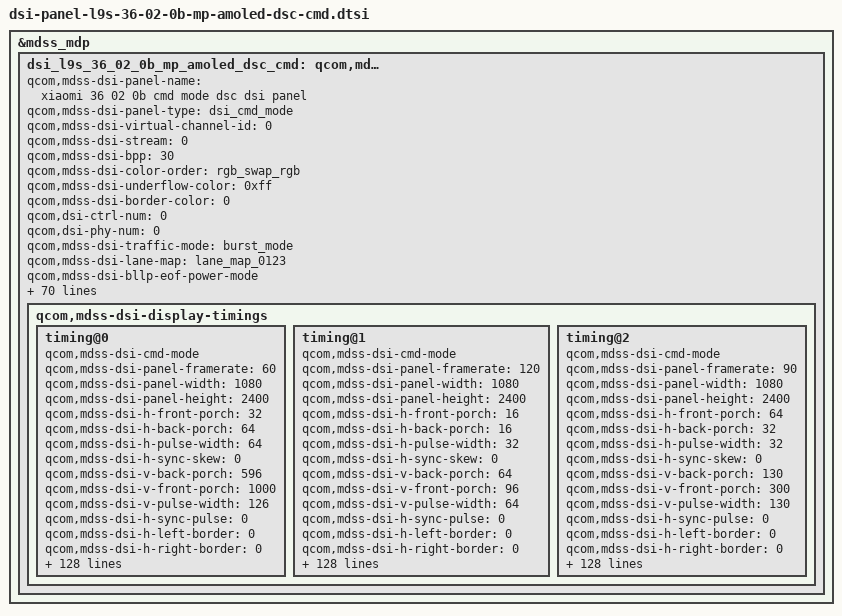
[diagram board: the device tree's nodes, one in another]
&mdss_mdp {
	dsi_l9s_36_02_0b_mp_amoled_dsc_cmd: qcom,mdss_dsi_l9s_36_02_0b_mp_amoled_dsc_cmd {
		qcom,mdss-dsi-panel-name = "xiaomi 36 02 0b cmd mode dsc dsi panel";
		qcom,mdss-dsi-panel-type = "dsi_cmd_mode";
		qcom,mdss-dsi-virtual-channel-id = <0>;
		qcom,mdss-dsi-stream = <0>;
		qcom,mdss-dsi-bpp = <30>;
		qcom,mdss-dsi-color-order = "rgb_swap_rgb";
		qcom,mdss-dsi-underflow-color = <0xff>;
		qcom,mdss-dsi-border-color = <0>;

		qcom,dsi-ctrl-num = <0>;
		qcom,dsi-phy-num = <0>;

		qcom,mdss-dsi-traffic-mode = "burst_mode";
		qcom,mdss-dsi-lane-map = "lane_map_0123";
		qcom,mdss-dsi-bllp-eof-power-mode;
		qcom,mdss-dsi-bllp-power-mode;
		qcom,mdss-dsi-lane-0-state;
		qcom,mdss-dsi-lane-1-state;
		qcom,mdss-dsi-lane-2-state;
		qcom,mdss-dsi-lane-3-state;
		qcom,mdss-dsi-dma-trigger = "trigger_sw";
		qcom,mdss-dsi-mdp-trigger = "none";
		qcom,mdss-dsi-reset-sequence =  <1 11>, <0 1>, <1 11>;
		qcom,mdss-pan-physical-width-dimension = <683>;
		qcom,mdss-pan-physical-height-dimension = <1517>;
		qcom,mdss-dsi-te-pin-select = <1>;
		qcom,mdss-dsi-wr-mem-start = <0x2c>;
		qcom,mdss-dsi-wr-mem-continue = <0x3c>;
		qcom,mdss-dsi-te-dcs-command = <1>;
		qcom,mdss-dsi-te-check-enable;
		qcom,mdss-dsi-te-using-te-pin;
		qcom,mdss-dsi-tx-eot-append;
		qcom,mdss-dsi-lp11-init;

		qcom,mdss-dsi-bl-inverted-dbv;
		qcom,bl-update-flag = "delay_until_first_frame";
		qcom,mdss-dsi-panel-mode-switch;

		qcom,mdss-dsi-panel-hdr-enabled;
		qcom,mdss-dsi-panel-hdr-color-primaries = <14500 15500 32000 17000 15500 30000 8000 3000>;
		qcom,mdss-dsi-panel-peak-brightness = <4200000>;
		qcom,mdss-dsi-panel-blackness-level = <3230>;

		qcom,mdss-dsi-display-timings {
			timing@0{
				qcom,mdss-dsi-cmd-mode;
				qcom,mdss-dsi-panel-framerate = <60>;
				qcom,mdss-dsi-panel-width = <1080>;
				qcom,mdss-dsi-panel-height = <2400>;
				qcom,mdss-dsi-h-front-porch = <32>;
				qcom,mdss-dsi-h-back-porch = <64>;
				qcom,mdss-dsi-h-pulse-width = <64>;
				qcom,mdss-dsi-h-sync-skew = <0>;
				qcom,mdss-dsi-v-back-porch = <596>;
				qcom,mdss-dsi-v-front-porch = <1000>;
				qcom,mdss-dsi-v-pulse-width = <126>;
				qcom,mdss-dsi-h-sync-pulse = <0>;
				qcom,mdss-dsi-h-left-border = <0>;
				qcom,mdss-dsi-h-right-border = <0>;
				qcom,mdss-dsi-v-top-border = <0>;
				qcom,mdss-dsi-v-bottom-border = <0>;
				qcom,mdss-dsi-panel-clockrate = <831000000>;
				qcom,mdss-dsi-panel-jitter = <0x5 0x1>;
				qcom,mdss-mdp-transfer-time-us = <14000>;
				qcom,mdss-dsi-on-command = [
					/* Page 0 */
					39 00 00 00 00 00 06 F0 55 AA 52 08 00
					39 00 00 40 00 00 02 6F 1C
					/* Gain mapping */
					39 00 00 40 00 00 06 C0 10 20 30 40 50
					/* VBP & VFP */
					39 00 00 40 00 00 05 3B 00 10 00 04
					/* DSC Setting */
					39 00 00 40 00 00 02 90 01
					39 00 00 40 00 00 13 91 89 28 00 0C C2 00 03 1C 01 7E 00 0F 08 BB 04 3D 10 F0
					39 00 00 40 00 00 02 03 01
					/* Dimming OFF Setting */
					39 00 00 40 00 00 02 53 20
					/* TE ON Setting */
					39 00 00 40 00 00 02 35 00
					/* CASET/RASET Setting */
					39 00 00 40 00 00 05 2A 00 00 04 37 /* CASET 1080 */
					39 00 00 40 00 00 05 2B 00 00 09 5F /* PASET 2400 */
					/* Frame Rate 60Hz */
					39 00 00 40 00 00 02 2F 03
					/* GIR OFF */
					39 00 00 40 00 00 02 5F 01
					/* ESD Error flag  Active low */
					39 00 00 40 00 00 06 F0 55 AA 52 08 00
					39 00 00 40 00 00 03 BE 0E 0B
					39 00 00 40 00 00 02 6F 05
					39 00 00 00 00 00 02 BE 8A
					/* Round Off */
					39 00 00 40 00 00 06 F0 55 AA 52 08 07
					39 00 00 40 00 00 02 C0 01
					39 00 00 40 00 00 02 C1 00
					39 00 00 40 00 00 02 C2 00
					39 00 00 40 00 00 02 C3 00
					39 00 00 40 00 00 02 C4 00
					39 00 00 40 00 00 02 C5 00
					39 00 00 40 00 00 02 C6 00
					39 00 00 40 00 00 02 C7 00
					39 00 00 40 00 00 02 C8 00
					39 00 00 40 00 00 02 C9 00
					39 00 00 40 00 00 02 CA 00
					39 00 00 40 00 00 02 CB 00
					39 00 00 00 00 00 02 CC 00
					/*OSC Setting*/
					39 00 00 40 00 00 05 FF AA 55 A5 81
					39 00 00 40 00 00 02 6F 0F
					39 00 00 40 00 00 03 FD 01 92
					39 00 00 00 00 00 02 2C 00
					39 00 00 00 00 00 06 F0 55 AA 52 08 07
					39 00 00 40 00 00 07 C0 01 01 00 00 00 55
					39 00 00 40 00 00 2C CD 21 00 22 84 22 84 00 00 3F E6 A7 10 3F E6 A7 10 80 04 A7 54 10 81 BD 15 82 1B 73 33 B0 22 84 0F A2 A2 00 00 00 00 00 00 00 00 00
					39 00 00 40 00 00 2C CE 27 00 22 84 22 84 00 00 00 00 00 00 3F E6 A7 10 80 00 00 00 00 82 1C 15 82 7A 73 33 B0 00 00 03 5E A2 00 00 00 00 00 00 00 00 00
					39 00 00 40 00 00 2C CF 2D 00 22 84 22 84 00 00 3F E6 A7 10 80 00 00 00 00 00 00 00 00 81 BD 74 82 1B D2 33 20 00 00 0C A2 5E 00 00 00 00 00 00 00 00 00
					39 00 00 00 00 00 2C D0 2B 00 22 84 22 84 00 00 00 00 00 00 80 00 00 00 7F FB 58 AB F0 82 1C 74 82 7A D2 33 2F DD 7C 00 5E 5E 00 00 00 00 00 00 00 00 00
					//FPR_W_THD
					39 00 00 40 00 00 02 D9 01
					39 00 00 40 00 00 06 F0 55 AA 52 08 00
					//DBV_DIM_FP
					39 00 00 40 00 00 02 6F 17
					39 00 00 40 00 00 03 B2 01 48
					//EM_DT_FP
					39 00 00 40 00 00 02 6F 1F
					39 00 00 00 00 00 03 B2 00 0C
					//sRGB_EN = 1
					39 00 00 40 00 00 02 DE 01
					//sRGB_Ratio_R/G/B (0 ~ 256 --> 0 ~ 1.0)
					39 00 00 40 00 00 02 6F 01
					39 00 00 40 00 00 07 DE 01 00 01 00 01 00
					39 00 00 40 00 00 06 F0 55 AA 52 08 02
					//Data + Gamma Mode
					39 00 00 40 00 00 02 D1 41
					//FPR_GAMMA_REDUCE_X/Y
					39 00 00 40 00 00 02 6F 02
					39 00 00 40 00 00 02 D1 00
					//FPR1_CENTER_X/Y_REF
					39 00 00 40 00 00 02 6F 03
					39 00 00 40 00 00 05 D1 02 1C 08 74
					//FPR1_START_X/Y_REF
					39 00 00 40 00 00 02 6F 07
					39 00 00 40 00 00 05 D1 01 BD 08 15
					//FPR1_END_X/Y_REF
					39 00 00 40 00 00 02 6F 0B
					39 00 00 00 00 00 05 D1 02 7A 08 D2
					//FPR_LHBM_R/G/B
					39 00 00 40 00 00 02 6F 0F
					39 00 00 40 00 00 07 D1 3F FC 3F FC 3F FC
					//GAMMA_TOUCH_R/G/B
					39 00 00 40 00 00 02 6F 08
					39 00 00 40 00 00 07 D0 0C 7B 0B 70 0C B0
					//FPR1_EN = 1
					39 00 00 40 00 00 02 88 01
					//FPR_CENTER_XY
					39 00 00 40 00 00 02 6F 01
					39 00 00 00 00 00 05 88 02 1C 08 73
					39 00 00 40 00 00 06 F0 55 AA 52 08 00
					39 00 00 40 00 00 02 B2 19
					39 00 00 40 00 00 02 6F 02
					39 00 00 00 00 00 03 B2 08 08
					39 00 00 40 00 00 02 6F 05
					39 00 00 00 00 00 02 BE 88
					/* Sleep Out */
					39 00 00 00 78 00 02 11 00
					/* Display On */
					39 00 00 00 00 00 02 29 00];
				qcom,mdss-dsi-off-command = [
					39 00 00 00 0A 00 02 28 00
					39 00 00 00 78 00 02 10 00];
				qcom,mdss-dsi-on-command-state = "dsi_lp_mode";
				qcom,mdss-dsi-off-command-state = "dsi_lp_mode";

				qcom,mdss-dsi-timing-switch-command = [
					/* Frame Rate 60Hz*/
					39 00 00 00 00 00 02 2F 03
				];
				qcom,mdss-dsi-timing-switch-command-update = <0x2F 0 1>;
				qcom,mdss-dsi-timing-switch-command-state = "dsi_hs_mode";

				qcom,mdss-dsi-nolp-command = [
					39 00 00 00 00 00 06 F0 55 AA 52 08 00
					39 00 00 40 00 00 02 38 00
					39 00 00 00 00 00 02 2C 00];
				qcom,mdss-dsi-nolp-command-state = "dsi_hs_mode";

				qcom,compression-mode = "dsc";
				qcom,mdss-dsc-version = <0x11>;
				qcom,mdss-dsc-scr-version = <0x0>;
				qcom,mdss-dsc-slice-height = <12>;
				qcom,mdss-dsc-slice-width = <1080>;
				qcom,mdss-dsc-slice-per-pkt = <1>;
				qcom,mdss-dsc-bit-per-component = <10>;
				qcom,mdss-dsc-bit-per-pixel = <8>;
				qcom,mdss-dsc-block-prediction-enable;
			};
			timing@1{
				qcom,mdss-dsi-cmd-mode;
				qcom,mdss-dsi-panel-framerate = <120>;
				qcom,mdss-dsi-panel-width = <1080>;
				qcom,mdss-dsi-panel-height = <2400>;
				qcom,mdss-dsi-h-front-porch = <16>;
				qcom,mdss-dsi-h-back-porch = <16>;
				qcom,mdss-dsi-h-pulse-width = <32>;
				qcom,mdss-dsi-h-sync-skew = <0>;
				qcom,mdss-dsi-v-back-porch = <64>;
				qcom,mdss-dsi-v-front-porch = <96>;
				qcom,mdss-dsi-v-pulse-width = <64>;
				qcom,mdss-dsi-h-sync-pulse = <0>;
				qcom,mdss-dsi-h-left-border = <0>;
				qcom,mdss-dsi-h-right-border = <0>;
				qcom,mdss-dsi-v-top-border = <0>;
				qcom,mdss-dsi-v-bottom-border = <0>;
				qcom,mdss-dsi-panel-clockrate = <831000000>;
				qcom,mdss-dsi-panel-jitter = <0x5 0x1>;
				qcom,mdss-mdp-transfer-time-us = <8000>;
				qcom,mdss-dsi-on-command = [
					/* Page 0 */
					39 00 00 00 00 00 06 F0 55 AA 52 08 00
					39 00 00 40 00 00 02 6F 1C
					/* Gain mapping */
					39 00 00 40 00 00 06 C0 10 20 30 40 50
					/* VBP & VFP */
					39 00 00 40 00 00 05 3B 00 10 00 04
					/* DSC Setting */
					39 00 00 40 00 00 02 90 01
					39 00 00 40 00 00 13 91 89 28 00 0C C2 00 03 1C 01 7E 00 0F 08 BB 04 3D 10 F0
					39 00 00 40 00 00 02 03 01
					/* Dimming OFF Setting */
					39 00 00 40 00 00 02 53 20
					/* TE ON Setting */
					39 00 00 40 00 00 02 35 00
					/* CASET/RASET Setting */
					39 00 00 40 00 00 05 2A 00 00 04 37 /* CASET 1080 */
					39 00 00 40 00 00 05 2B 00 00 09 5F /* PASET 2400 */
					/* Frame Rate 120Hz */
					39 00 00 40 00 00 02 2F 01
					/* GIR OFF */
					39 00 00 40 00 00 02 5F 01
					/* ESD Error flag  Active low */
					39 00 00 40 00 00 06 F0 55 AA 52 08 00
					39 00 00 40 00 00 03 BE 0E 0B
					39 00 00 40 00 00 02 6F 05
					39 00 00 00 00 00 02 BE 8A
					/* Round Off */
					39 00 00 40 00 00 06 F0 55 AA 52 08 07
					39 00 00 40 00 00 02 C0 01
					39 00 00 40 00 00 02 C1 00
					39 00 00 40 00 00 02 C2 00
					39 00 00 40 00 00 02 C3 00
					39 00 00 40 00 00 02 C4 00
					39 00 00 40 00 00 02 C5 00
					39 00 00 40 00 00 02 C6 00
					39 00 00 40 00 00 02 C7 00
					39 00 00 40 00 00 02 C8 00
					39 00 00 40 00 00 02 C9 00
					39 00 00 40 00 00 02 CA 00
					39 00 00 40 00 00 02 CB 00
					39 00 00 00 00 00 02 CC 00
					/*OSC Setting*/
					39 00 00 40 00 00 05 FF AA 55 A5 81
					39 00 00 40 00 00 02 6F 0F
					39 00 00 40 00 00 03 FD 01 92
					39 00 00 00 00 00 02 2C 00
					39 00 00 00 00 00 06 F0 55 AA 52 08 07
					39 00 00 40 00 00 07 C0 01 01 00 00 00 55
					39 00 00 40 00 00 2C CD 21 00 22 84 22 84 00 00 3F E6 A7 10 3F E6 A7 10 80 04 A7 54 10 81 BD 15 82 1B 73 33 B0 22 84 0F A2 A2 00 00 00 00 00 00 00 00 00
					39 00 00 40 00 00 2C CE 27 00 22 84 22 84 00 00 00 00 00 00 3F E6 A7 10 80 00 00 00 00 82 1C 15 82 7A 73 33 B0 00 00 03 5E A2 00 00 00 00 00 00 00 00 00
					39 00 00 40 00 00 2C CF 2D 00 22 84 22 84 00 00 3F E6 A7 10 80 00 00 00 00 00 00 00 00 81 BD 74 82 1B D2 33 20 00 00 0C A2 5E 00 00 00 00 00 00 00 00 00
					39 00 00 00 00 00 2C D0 2B 00 22 84 22 84 00 00 00 00 00 00 80 00 00 00 7F FB 58 AB F0 82 1C 74 82 7A D2 33 2F DD 7C 00 5E 5E 00 00 00 00 00 00 00 00 00
					//FPR_W_THD
					39 00 00 40 00 00 02 D9 01
					39 00 00 40 00 00 06 F0 55 AA 52 08 00
					//DBV_DIM_FP
					39 00 00 40 00 00 02 6F 17
					39 00 00 40 00 00 03 B2 01 48
					//EM_DT_FP
					39 00 00 40 00 00 02 6F 1F
					39 00 00 00 00 00 03 B2 00 0C
					//sRGB_EN = 1
					39 00 00 40 00 00 02 DE 01
					//sRGB_Ratio_R/G/B (0 ~ 256 --> 0 ~ 1.0)
					39 00 00 40 00 00 02 6F 01
					39 00 00 40 00 00 07 DE 01 00 01 00 01 00
					39 00 00 40 00 00 06 F0 55 AA 52 08 02
					//Data + Gamma Mode
					39 00 00 40 00 00 02 D1 41
					//FPR_GAMMA_REDUCE_X/Y
					39 00 00 40 00 00 02 6F 02
					39 00 00 40 00 00 02 D1 00
					//FPR1_CENTER_X/Y_REF
					39 00 00 40 00 00 02 6F 03
					39 00 00 40 00 00 05 D1 02 1C 08 74
					//FPR1_START_X/Y_REF
					39 00 00 40 00 00 02 6F 07
					39 00 00 40 00 00 05 D1 01 BD 08 15
					//FPR1_END_X/Y_REF
					39 00 00 40 00 00 02 6F 0B
					39 00 00 00 00 00 05 D1 02 7A 08 D2
					//FPR_LHBM_R/G/B
					39 00 00 40 00 00 02 6F 0F
					39 00 00 40 00 00 07 D1 3F FC 3F FC 3F FC
					//GAMMA_TOUCH_R/G/B
					39 00 00 40 00 00 02 6F 08
					39 00 00 40 00 00 07 D0 0C 7B 0B 70 0C B0
					//FPR1_EN = 1
					39 00 00 40 00 00 02 88 01
					//FPR_CENTER_XY
					39 00 00 40 00 00 02 6F 01
					39 00 00 00 00 00 05 88 02 1C 08 73
					39 00 00 40 00 00 06 F0 55 AA 52 08 00
					39 00 00 40 00 00 02 B2 19
					39 00 00 40 00 00 02 6F 02
					39 00 00 00 00 00 03 B2 08 08
					39 00 00 40 00 00 02 6F 05
					39 00 00 00 00 00 02 BE 88
					/* Sleep Out */
					39 00 00 00 78 00 02 11 00
					/* Display On */
					39 00 00 00 00 00 02 29 00];
				qcom,mdss-dsi-off-command = [
					39 00 00 00 14 00 02 28 00
					39 00 00 00 78 00 02 10 00];
				qcom,mdss-dsi-on-command-state = "dsi_lp_mode";
				qcom,mdss-dsi-off-command-state = "dsi_lp_mode";

				qcom,mdss-dsi-timing-switch-command = [
					/* Frame Rate 120Hz */
					39 00 00 00 00 00 02 2F 01
				];
				qcom,mdss-dsi-timing-switch-command-update = <0x2F 0 1>;
				qcom,mdss-dsi-timing-switch-command-state = "dsi_hs_mode";

				qcom,mdss-dsi-nolp-command = [
					39 00 00 00 00 00 06 F0 55 AA 52 08 00
					39 00 00 40 00 00 02 38 00
					39 00 00 00 00 00 02 2C 00];
				qcom,mdss-dsi-nolp-command-state = "dsi_hs_mode";

				qcom,compression-mode = "dsc";
				qcom,mdss-dsc-version = <0x11>;
				qcom,mdss-dsc-scr-version = <0x0>;
				qcom,mdss-dsc-slice-height = <12>;
				qcom,mdss-dsc-slice-width = <1080>;
				qcom,mdss-dsc-slice-per-pkt = <1>;
				qcom,mdss-dsc-bit-per-component = <10>;
				qcom,mdss-dsc-bit-per-pixel = <8>;
				qcom,mdss-dsc-block-prediction-enable;
			};
			timing@2{
				qcom,mdss-dsi-cmd-mode;
				qcom,mdss-dsi-panel-framerate = <90>;
				qcom,mdss-dsi-panel-width = <1080>;
				qcom,mdss-dsi-panel-height = <2400>;
				qcom,mdss-dsi-h-front-porch = <64>;
				qcom,mdss-dsi-h-back-porch = <32>;
				qcom,mdss-dsi-h-pulse-width = <32>;
				qcom,mdss-dsi-h-sync-skew = <0>;
				qcom,mdss-dsi-v-back-porch = <130>;
				qcom,mdss-dsi-v-front-porch = <300>;
				qcom,mdss-dsi-v-pulse-width = <130>;
				qcom,mdss-dsi-h-sync-pulse = <0>;
				qcom,mdss-dsi-h-left-border = <0>;
				qcom,mdss-dsi-h-right-border = <0>;
				qcom,mdss-dsi-v-top-border = <0>;
				qcom,mdss-dsi-v-bottom-border = <0>;
				qcom,mdss-dsi-panel-clockrate = <831000000>;
				qcom,mdss-dsi-panel-jitter = <0x5 0x1>;
				qcom,mdss-mdp-transfer-time-us = <10000>;
				qcom,mdss-dsi-on-command = [
					/* Page 0 */
					39 00 00 00 00 00 06 F0 55 AA 52 08 00
					39 00 00 40 00 00 02 6F 1C
					/* Gain mapping */
					39 00 00 40 00 00 06 C0 10 20 30 40 50
					/* VBP & VFP */
					39 00 00 40 00 00 05 3B 00 10 00 04
					/* DSC Setting */
					39 00 00 40 00 00 02 90 01
					39 00 00 40 00 00 13 91 89 28 00 0C C2 00 03 1C 01 7E 00 0F 08 BB 04 3D 10 F0
					39 00 00 40 00 00 02 03 01
					/* Dimming OFF Setting */
					39 00 00 40 00 00 02 53 20
					/* TE ON Setting */
					39 00 00 40 00 00 02 35 00
					/* CASET/RASET Setting */
					39 00 00 40 00 00 05 2A 00 00 04 37 /* CASET 1080 */
					39 00 00 40 00 00 05 2B 00 00 09 5F /* PASET 2400 */
					/* Frame Rate 60Hz */
					39 00 00 40 00 00 02 2F 07
					/* GIR OFF */
					39 00 00 40 00 00 02 5F 01
					/* ESD Error flag  Active low */
					39 00 00 40 00 00 06 F0 55 AA 52 08 00
					39 00 00 40 00 00 03 BE 0E 0B
					39 00 00 40 00 00 02 6F 05
					39 00 00 00 00 00 02 BE 8A
					/* Round Off */
					39 00 00 40 00 00 06 F0 55 AA 52 08 07
					39 00 00 40 00 00 02 C0 01
					39 00 00 40 00 00 02 C1 00
					39 00 00 40 00 00 02 C2 00
					39 00 00 40 00 00 02 C3 00
					39 00 00 40 00 00 02 C4 00
					39 00 00 40 00 00 02 C5 00
					39 00 00 40 00 00 02 C6 00
					39 00 00 40 00 00 02 C7 00
					39 00 00 40 00 00 02 C8 00
					39 00 00 40 00 00 02 C9 00
					39 00 00 40 00 00 02 CA 00
					39 00 00 40 00 00 02 CB 00
					39 00 00 00 00 00 02 CC 00
					/*OSC Setting*/
					39 00 00 40 00 00 05 FF AA 55 A5 81
					39 00 00 40 00 00 02 6F 0F
					39 00 00 40 00 00 03 FD 01 92
					39 00 00 00 00 00 02 2C 00
					39 00 00 00 00 00 06 F0 55 AA 52 08 07
					39 00 00 40 00 00 07 C0 01 01 00 00 00 55
					39 00 00 40 00 00 2C CD 21 00 22 84 22 84 00 00 3F E6 A7 10 3F E6 A7 10 80 04 A7 54 10 81 BD 15 82 1B 73 33 B0 22 84 0F A2 A2 00 00 00 00 00 00 00 00 00
					39 00 00 40 00 00 2C CE 27 00 22 84 22 84 00 00 00 00 00 00 3F E6 A7 10 80 00 00 00 00 82 1C 15 82 7A 73 33 B0 00 00 03 5E A2 00 00 00 00 00 00 00 00 00
					39 00 00 40 00 00 2C CF 2D 00 22 84 22 84 00 00 3F E6 A7 10 80 00 00 00 00 00 00 00 00 81 BD 74 82 1B D2 33 20 00 00 0C A2 5E 00 00 00 00 00 00 00 00 00
					39 00 00 00 00 00 2C D0 2B 00 22 84 22 84 00 00 00 00 00 00 80 00 00 00 7F FB 58 AB F0 82 1C 74 82 7A D2 33 2F DD 7C 00 5E 5E 00 00 00 00 00 00 00 00 00
					//FPR_W_THD
					39 00 00 40 00 00 02 D9 01
					39 00 00 40 00 00 06 F0 55 AA 52 08 00
					//DBV_DIM_FP
					39 00 00 40 00 00 02 6F 17
					39 00 00 40 00 00 03 B2 01 48
					//EM_DT_FP
					39 00 00 40 00 00 02 6F 1F
					39 00 00 00 00 00 03 B2 00 0C
					//sRGB_EN = 1
					39 00 00 40 00 00 02 DE 01
					//sRGB_Ratio_R/G/B (0 ~ 256 --> 0 ~ 1.0)
					39 00 00 40 00 00 02 6F 01
					39 00 00 40 00 00 07 DE 01 00 01 00 01 00
					39 00 00 40 00 00 06 F0 55 AA 52 08 02
					//Data + Gamma Mode
					39 00 00 40 00 00 02 D1 41
					//FPR_GAMMA_REDUCE_X/Y
					39 00 00 40 00 00 02 6F 02
					39 00 00 40 00 00 02 D1 00
					//FPR1_CENTER_X/Y_REF
					39 00 00 40 00 00 02 6F 03
					39 00 00 40 00 00 05 D1 02 1C 08 74
					//FPR1_START_X/Y_REF
					39 00 00 40 00 00 02 6F 07
					39 00 00 40 00 00 05 D1 01 BD 08 15
					//FPR1_END_X/Y_REF
					39 00 00 40 00 00 02 6F 0B
					39 00 00 00 00 00 05 D1 02 7A 08 D2
					//FPR_LHBM_R/G/B
					39 00 00 40 00 00 02 6F 0F
					39 00 00 40 00 00 07 D1 3F FC 3F FC 3F FC
					//GAMMA_TOUCH_R/G/B
					39 00 00 40 00 00 02 6F 08
					39 00 00 40 00 00 07 D0 0C 7B 0B 70 0C B0
					//FPR1_EN = 1
					39 00 00 40 00 00 02 88 01
					//FPR_CENTER_XY
					39 00 00 40 00 00 02 6F 01
					39 00 00 00 00 00 05 88 02 1C 08 73
					39 00 00 40 00 00 06 F0 55 AA 52 08 00
					39 00 00 40 00 00 02 B2 19
					39 00 00 40 00 00 02 6F 02
					39 00 00 00 00 00 03 B2 08 08
					39 00 00 40 00 00 02 6F 05
					39 00 00 00 00 00 02 BE 88
					/* Sleep Out */
					39 00 00 00 78 00 02 11 00
					/* Display On */
					39 00 00 00 00 00 02 29 00];
				qcom,mdss-dsi-off-command = [
					39 00 00 00 0A 00 02 28 00
					39 00 00 00 78 00 02 10 00];
				qcom,mdss-dsi-on-command-state = "dsi_lp_mode";
				qcom,mdss-dsi-off-command-state = "dsi_lp_mode";

				qcom,mdss-dsi-timing-switch-command = [
					/* Frame Rate 90Hz */
					39 00 00 00 00 00 02 2F 07
				];
				qcom,mdss-dsi-timing-switch-command-update = <0x2F 0 1>;
				qcom,mdss-dsi-timing-switch-command-state = "dsi_hs_mode";

				qcom,mdss-dsi-nolp-command = [
					39 00 00 00 00 00 06 F0 55 AA 52 08 00
					39 00 00 40 00 00 02 38 00
					39 00 00 00 00 00 02 2C 00];
				qcom,mdss-dsi-nolp-command-state = "dsi_hs_mode";

				qcom,compression-mode = "dsc";
				qcom,mdss-dsc-version = <0x11>;
				qcom,mdss-dsc-scr-version = <0x0>;
				qcom,mdss-dsc-slice-height = <12>;
				qcom,mdss-dsc-slice-width = <1080>;
				qcom,mdss-dsc-slice-per-pkt = <1>;
				qcom,mdss-dsc-bit-per-component = <10>;
				qcom,mdss-dsc-bit-per-pixel = <8>;
				qcom,mdss-dsc-block-prediction-enable;
			};
		};
	};
};

&dsi_l9s_36_02_0b_mp_amoled_dsc_cmd {
	mi,panel-id = <0x004C3953 0x00360200>;
	mi,hbm-51-ctl-flag;
	mi,bl-51ctl-32bit-flag;
	mi,aod-bl-51ctl-flag;
	mi,aod-brightness = <0x1FF 0x03FF>;
	mi,hbm-off-51-index = <0>;
	mi,hbm-fod-off-51-index = <0>;
	mi,hbm-bl-min-level = <1>;
	mi,hbm-bl-max-level = <2047>;
	mi,max-brightness-clone = <4095>;
	mi,thermal-dimming-flag;
	mi,mdss-dsi-panel-dc-type = <0>;
	mi,local-hbm-enabled;
	mi,doze-hbm-dbv-level = <245>;
	mi,doze-lbm-dbv-level = <20>;
	mi,fod-low-brightness-clone-threshold = <38>;
	mi,fod-low-brightness-lux-threshold = <1>;
	mi,mdss-dsi-fac-bl-max-level = <2047>;
	mi,mdss-fac-brightness-max-level = <2047>;
	mi,local-hbm-white-1000nit-update-flag;
	mi,local-hbm-white-110nit-update-flag;
	mi,local-hbm-green-500nit-update-flag;
	mi,local-hbm-alpha-ctrl-aa-area;
	mi,local-hbm-ctrl-b2-reg;
	mi,need-fod-animal-in-normal-enabled;

	mi,flat-need-sync-te;

	mi,panel-hbm-backlight-threshold = <2047>;

	/* IRQF_ONESHOT | IRQF_TRIGGER_LOW */
	mi,esd-err-irq-gpio = <&tlmm 11 0x2008>;

	mi,panel-aod-to-off-command-need-enabled;

	mi,panel-on-dimming-delay = <120>;

	qcom,esd-check-enabled;
	qcom,esd-aod-check-enabled;
	qcom,mdss-dsi-panel-status-check-mode = "reg_read";
	qcom,mdss-dsi-panel-status-offset-command = [
		39 00 00 00 00 00 05 FF AA 55 A5 81
		39 00 00 00 00 00 02 6F 0F];
	qcom,mdss-dsi-panel-status-command = [06 00 00 00 00 00 01 FA];
	qcom,mdss-dsi-panel-status-command-state = "dsi_lp_mode";
	qcom,mdss-dsi-panel-status-offset-command-state = "dsi_lp_mode";
	qcom,mdss-dsi-panel-status-value = <0x00>;
	qcom,mdss-dsi-panel-status-read-length = <1>;

	qcom,mdss-dsi-display-timings {
		timing@0{ /* 60hz */
			/*<flat on gamma, flat off gamma>*/
			mi,mdss-flat-status-control-gamma-cfg = <0x04 0x03>;
			mi,mdss-dsc-panel-id = <0x004C3953 0x00360200>;
			mi,mdss-dsi-dimmingon-command = [39 00 00 00 00 00 02 53 28];
			mi,mdss-dsi-dimmingon-command-state = "dsi_hs_mode";
			mi,mdss-dsi-dimmingoff-command = [39 00 00 00 00 00 02 53 20];
			mi,mdss-dsi-dimmingoff-command-state = "dsi_hs_mode";

			mi,mdss-dsi-hbm-on-command = [39 00 00 00 00 00 03 51 0F FF];
			mi,mdss-dsi-hbm-on-command-state = "dsi_hs_mode";
			mi,mdss-dsi-hbm-off-command = [39 00 00 00 00 00 03 51 07 FF];
			mi,mdss-dsi-hbm-off-command-state = "dsi_hs_mode";

			mi,mdss-dsi-doze-hbm-command = [
				39 00 00 00 00 00 06 F0 55 AA 52 08 00
				39 00 00 40 00 00 05 51 00 F5 03 FF
				39 00 00 40 00 00 02 39 00
				39 00 00 00 00 00 02 2C 00
			];
			mi,mdss-dsi-doze-hbm-command-state = "dsi_lp_mode";
			mi,mdss-dsi-doze-lbm-command = [
				39 00 00 00 00 00 06 F0 55 AA 52 08 00
				39 00 00 40 00 00 05 51 00 14 01 FF
				39 00 00 40 00 00 02 39 00
				39 00 00 00 00 00 02 2C 00
			];
			mi,mdss-dsi-doze-lbm-command-state = "dsi_lp_mode";

			mi,mdss-dsi-doze-hbm-nolp-command = [
				/* AOD off */
				39 00 00 00 00 00 06 F0 55 AA 52 08 00
				39 00 00 40 00 00 05 51 00 F5 03 FF
				39 00 00 40 00 00 02 38 00
				39 00 00 00 00 00 02 2C 00
			];
			mi,mdss-dsi-doze-hbm-nolp-command-state = "dsi_lp_mode";
			mi,mdss-dsi-doze-lbm-nolp-command = [
				/* AOD off */
				39 00 00 00 00 00 06 F0 55 AA 52 08 00
				39 00 00 40 00 00 05 51 00 14 01 FF
				39 00 00 40 00 00 02 38 00
				39 00 00 00 00 00 02 2C 00
			];
			mi,mdss-dsi-doze-lbm-nolp-command-state = "dsi_lp_mode";

			mi,mdss-dsi-doze-none-nolp-command = [
				/* AOD off */
				39 00 00 00 00 00 02 38 00
				39 00 00 00 00 00 02 2C 00
			];
			mi,mdss-dsi-doze-none-nolp-command-state = "dsi_lp_mode";

			mi,mdss-dsi-local-hbm-normal-white-1000nit-command = [
				39 00 00 00 00 00 06 F0 55 AA 52 08 00
				39 00 00 40 00 00 02 6F 17
				39 00 00 40 00 00 03 B2 01 48
				39 00 00 40 00 00 06 F0 55 AA 52 08 02
				39 00 00 40 00 00 02 6F 08
				39 00 00 40 00 00 07 D0 0B 0A 0A EC 0B FD
				39 00 00 40 00 00 02 88 01
				39 00 00 40 00 00 02 6F 01
				39 00 00 40 00 00 05 88 02 1C 08 73
				39 00 00 40 00 00 03 87 1F FF
				39 00 00 00 42 00 02 85 01
			];
			mi,mdss-dsi-local-hbm-normal-white-1000nit-command-update = <0x87 9 2>, <0xD0 5 6>, <0xB2 2 2>;
			mi,mdss-dsi-local-hbm-normal-white-1000nit-command-state = "dsi_hs_mode";

			mi,mdss-dsi-local-hbm-hlpm-white-1000nit-command = [
				/* AOD off */
				39 00 00 00 00 00 06 F0 55 AA 52 08 00
				39 00 00 40 00 00 02 38 00
				39 00 00 00 00 00 02 2C 00
				/* Local HBM setting*/
				39 00 00 00 00 00 06 F0 55 AA 52 08 00
				39 00 00 40 00 00 02 6F 17
				39 00 00 40 00 00 03 B2 01 48
				39 00 00 40 00 00 06 F0 55 AA 52 08 02
				39 00 00 40 00 00 02 6F 08
				39 00 00 40 00 00 07 D0 0B 0A 0A EC 0B FD
				39 00 00 40 00 00 02 88 01
				39 00 00 40 00 00 02 6F 01
				39 00 00 40 00 00 05 88 02 1C 08 73
				39 00 00 40 00 00 03 87 1F FF
				39 00 00 00 42 00 02 85 01
			];
			mi,mdss-dsi-local-hbm-hlpm-white-1000nit-command-update = <0x87 12 2>, <0xD0 8 6>, <0xB2 5 2>;
			mi,mdss-dsi-local-hbm-hlpm-white-1000nit-command-state = "dsi_hs_mode";

			mi,mdss-dsi-local-hbm-normal-white-110nit-command = [
				39 00 00 00 00 00 06 F0 55 AA 52 08 00
				39 00 00 40 00 00 02 6F 17
				39 00 00 40 00 00 03 B2 01 48
				39 00 00 40 00 00 06 F0 55 AA 52 08 02
				39 00 00 40 00 00 02 6F 08
				39 00 00 40 00 00 07 D0 0B 0A 0A EC 0B FD
				39 00 00 40 00 00 02 88 01
				39 00 00 40 00 00 02 6F 01
				39 00 00 40 00 00 05 88 02 1C 08 73
				39 00 00 40 00 00 03 87 1F FF
				39 00 00 00 42 00 02 85 01
			];
			mi,mdss-dsi-local-hbm-normal-white-110nit-command-update = <0x87 9 2>, <0xD0 5 6>, <0xB2 2 2>;
			mi,mdss-dsi-local-hbm-normal-white-110nit-command-state = "dsi_hs_mode";

			mi,mdss-dsi-local-hbm-hlpm-white-110nit-command = [
				39 00 00 00 00 00 06 F0 55 AA 52 08 00
				/* AOD off */
				39 00 00 40 00 00 02 38 00
				39 00 00 00 00 00 02 2C 00
				/* Local HBM setting*/
				39 00 00 00 00 00 06 F0 55 AA 52 08 00
				39 00 00 40 00 00 02 6F 17
				39 00 00 40 00 00 03 B2 01 48
				39 00 00 40 00 00 06 F0 55 AA 52 08 02
				39 00 00 40 00 00 02 6F 08
				39 00 00 40 00 00 07 D0 0B 0A 0A EC 0B FD
				39 00 00 40 00 00 02 88 01
				39 00 00 40 00 00 02 6F 01
				39 00 00 40 00 00 05 88 02 1C 08 73
				39 00 00 40 00 00 03 87 1F FF
				39 00 00 00 42 00 02 85 01
			];
			mi,mdss-dsi-local-hbm-hlpm-white-110nit-command-update = <0x87 12 2>, <0xD0 8 6>, <0xB2 5 2>;
			mi,mdss-dsi-local-hbm-hlpm-white-110nit-command-state = "dsi_hs_mode";

			mi,mdss-dsi-local-hbm-normal-green-500nit-command = [
				39 00 00 00 00 00 06 F0 55 AA 52 08 00
				39 00 00 40 00 00 02 6F 17
				39 00 00 40 00 00 03 B2 01 48
				39 00 00 40 00 00 06 F0 55 AA 52 08 02
				39 00 00 40 00 00 02 6F 08
				39 00 00 40 00 00 07 D0 0B 0A 0A EC 0B FD
				39 00 00 40 00 00 02 88 01
				39 00 00 40 00 00 02 6F 01
				39 00 00 40 00 00 05 88 02 1C 08 73
				39 00 00 40 00 00 03 87 1F FF
				39 00 00 00 42 00 02 85 01
			];
			mi,mdss-dsi-local-hbm-normal-green-500nit-command-update = <0x87 9 2>, <0xD0 5 6>, <0xB2 2 2>;
			mi,mdss-dsi-local-hbm-normal-green-500nit-command-state = "dsi_hs_mode";

			mi,mdss-dsi-local-hbm-off-to-normal-command = [
				39 00 00 00 00 00 02 53 20
				39 00 00 40 00 00 03 51 00 00
				39 00 00 40 00 00 02 86 01
				39 00 00 00 00 00 03 87 0F FF
			];
			mi,mdss-dsi-local-hbm-off-to-normal-command-update = <0x51 1 2>;
			mi,mdss-dsi-local-hbm-off-to-normal-command-state = "dsi_hs_mode";

			mi,mdss-dsi-local-hbm-off-to-hbm-command = [
				39 00 00 00 00 00 02 53 20
				39 00 00 40 00 00 03 51 00 00
				39 00 00 40 00 00 02 86 01
				39 00 00 00 00 00 03 87 0F FF
			];
			mi,mdss-dsi-local-hbm-off-to-hbm-command-update = <0x51 1 2>;
			mi,mdss-dsi-local-hbm-off-to-hbm-command-state = "dsi_hs_mode";

			mi,mdss-dsi-local-hbm-off-to-hlpm-command = [
				/* local hbm off */
				39 00 00 00 00 00 02 53 20
				39 00 00 40 00 00 03 51 00 00
				39 00 00 40 00 00 02 86 01
				39 00 00 00 00 00 03 87 0F FF
				/* aod hbm */
				39 00 00 00 00 00 06 F0 55 AA 52 08 00
				39 00 00 40 00 00 05 51 00 F5 03 FF
				39 00 00 40 00 00 02 39 00
				39 00 00 00 00 00 02 2C 00
			];
			mi,mdss-dsi-local-hbm-off-to-hlpm-command-state = "dsi_hs_mode";

			mi,mdss-dsi-local-hbm-off-to-llpm-command = [
				/* local hbm off */
				39 00 00 00 00 00 02 53 20
				39 00 00 40 00 00 03 51 00 00
				39 00 00 40 00 00 02 86 01
				39 00 00 00 00 00 03 87 0F FF
				/* aod lbm */
				39 00 00 00 00 00 06 F0 55 AA 52 08 00
				39 00 00 40 00 00 05 51 00 14 01 FF
				39 00 00 40 00 00 02 39 00
				39 00 00 00 00 00 02 2C 00
			];
			mi,mdss-dsi-local-hbm-off-to-llpm-command-state = "dsi_hs_mode";

			mi,mdss-dsi-flat-mode-on-command = [
				/* page 0 */
				39 00 00 00 00 00 06 F0 55 AA 52 08 00
				/* 60Hz */
				39 00 00 40 00 00 02 2F 04
				/* GIR ON */
				39 00 00 20 14 00 02 5F 00
			];
			mi,mdss-dsi-flat-mode-on-command-state = "dsi_hs_mode";

			mi,mdss-dsi-flat-mode-off-command = [
				/* page 0 */
				39 00 00 00 00 00 06 F0 55 AA 52 08 00
				/* 60Hz */
				39 00 00 40 00 00 02 2F 03
				/* GIR OFF */
				39 00 00 20 14 00 02 5F 01
			];
			mi,mdss-dsi-flat-mode-off-command-state = "dsi_hs_mode";

			mi,mdss-dsi-pre-doze-to-off-command = [
				39 01 00 00 00 00 06 F0 55 AA 52 08 01
				39 01 00 00 00 00 02 CE 0C];
			mi,mdss-dsi-pre-doze-to-off-command-state = "dsi_hs_mode";
		};
		timing@1{ /* 120hz */
			/*<flat on gamma, flat off gamma>*/
			mi,mdss-flat-status-control-gamma-cfg = <0x02 0x01>;
			mi,mdss-dsc-panel-id = <0x004C3953 0x00360200>;
			mi,mdss-dsi-dimmingon-command = [39 00 00 00 00 00 02 53 28];
			mi,mdss-dsi-dimmingon-command-state = "dsi_hs_mode";
			mi,mdss-dsi-dimmingoff-command = [39 00 00 00 00 00 02 53 20];
			mi,mdss-dsi-dimmingoff-command-state = "dsi_hs_mode";

			mi,mdss-dsi-hbm-on-command = [39 00 00 00 00 00 03 51 0F FF];
			mi,mdss-dsi-hbm-on-command-state = "dsi_hs_mode";
			mi,mdss-dsi-hbm-off-command = [39 00 00 00 00 00 03 51 07 FF];
			mi,mdss-dsi-hbm-off-command-state = "dsi_hs_mode";

			mi,mdss-dsi-doze-hbm-command = [
				39 00 00 00 00 00 06 F0 55 AA 52 08 00
				39 00 00 40 00 00 05 51 00 F5 03 FF
				39 00 00 40 00 00 02 39 00
				39 00 00 00 00 00 02 2C 00
			];
			mi,mdss-dsi-doze-hbm-command-state = "dsi_lp_mode";
			mi,mdss-dsi-doze-lbm-command = [
				39 00 00 00 00 00 06 F0 55 AA 52 08 00
				39 00 00 40 00 00 05 51 00 14 01 FF
				39 00 00 40 00 00 02 39 00
				39 00 00 00 00 00 02 2C 00
			];
			mi,mdss-dsi-doze-lbm-command-state = "dsi_lp_mode";

			mi,mdss-dsi-doze-hbm-nolp-command = [
				/* AOD off */
				39 00 00 00 00 00 06 F0 55 AA 52 08 00
				39 00 00 40 00 00 05 51 00 F5 03 FF
				39 00 00 40 00 00 02 38 00
				39 00 00 00 00 00 02 2C 00
			];
			mi,mdss-dsi-doze-hbm-nolp-command-state = "dsi_lp_mode";
			mi,mdss-dsi-doze-lbm-nolp-command = [
				/* AOD off */
				39 00 00 00 00 00 06 F0 55 AA 52 08 00
				39 00 00 40 00 00 05 51 00 14 01 FF
				39 00 00 40 00 00 02 38 00
				39 00 00 00 00 00 02 2C 00
			];
			mi,mdss-dsi-doze-lbm-nolp-command-state = "dsi_lp_mode";

			mi,mdss-dsi-doze-none-nolp-command = [
				/* AOD off */
				39 00 00 00 00 00 02 38 00
				39 00 00 00 00 00 02 2C 00
			];
			mi,mdss-dsi-doze-none-nolp-command-state = "dsi_lp_mode";

			mi,mdss-dsi-local-hbm-normal-white-1000nit-command = [
				39 00 00 00 00 00 06 F0 55 AA 52 08 00
				39 00 00 40 00 00 02 6F 17
				39 00 00 40 00 00 03 B2 01 48
				39 00 00 40 00 00 06 F0 55 AA 52 08 02
				39 00 00 40 00 00 02 6F 08
				39 00 00 40 00 00 07 D0 0B 0A 0A EC 0B FD
				39 00 00 40 00 00 02 88 01
				39 00 00 40 00 00 02 6F 01
				39 00 00 40 00 00 05 88 02 1C 08 73
				39 00 00 40 00 00 03 87 1F FF
				39 00 00 00 20 00 02 85 01
			];
			mi,mdss-dsi-local-hbm-normal-white-1000nit-command-update = <0x87 9 2>, <0xD0 5 6>, <0xB2 2 2>;
			mi,mdss-dsi-local-hbm-normal-white-1000nit-command-state = "dsi_hs_mode";

			mi,mdss-dsi-local-hbm-hlpm-white-1000nit-command = [
				/* AOD off */
				39 00 00 00 00 00 06 F0 55 AA 52 08 00
				39 00 00 40 00 00 02 38 00
				39 00 00 00 00 00 02 2C 00
				/* Local HBM setting*/
				39 00 00 00 00 00 06 F0 55 AA 52 08 00
				39 00 00 40 00 00 02 6F 17
				39 00 00 40 00 00 03 B2 01 48
				39 00 00 40 00 00 06 F0 55 AA 52 08 02
				39 00 00 40 00 00 02 6F 08
				39 00 00 40 00 00 07 D0 0B 0A 0A EC 0B FD
				39 00 00 40 00 00 02 88 01
				39 00 00 40 00 00 02 6F 01
				39 00 00 40 00 00 05 88 02 1C 08 73
				39 00 00 40 00 00 03 87 1F FF
				39 00 00 00 20 00 02 85 01
			];
			mi,mdss-dsi-local-hbm-hlpm-white-1000nit-command-update = <0x87 12 2>, <0xD0 8 6>, <0xB2 5 2>;
			mi,mdss-dsi-local-hbm-hlpm-white-1000nit-command-state = "dsi_hs_mode";

			mi,mdss-dsi-local-hbm-normal-white-110nit-command = [
				39 00 00 00 00 00 06 F0 55 AA 52 08 00
				39 00 00 40 00 00 02 6F 17
				39 00 00 40 00 00 03 B2 01 48
				39 00 00 40 00 00 06 F0 55 AA 52 08 02
				39 00 00 40 00 00 02 6F 08
				39 00 00 40 00 00 07 D0 0B 0A 0A EC 0B FD
				39 00 00 40 00 00 02 88 01
				39 00 00 40 00 00 02 6F 01
				39 00 00 40 00 00 05 88 02 1C 08 73
				39 00 00 40 00 00 03 87 1F FF
				39 00 00 00 20 00 02 85 01
			];
			mi,mdss-dsi-local-hbm-normal-white-110nit-command-update = <0x87 9 2>, <0xD0 5 6>, <0xB2 2 2>;
			mi,mdss-dsi-local-hbm-normal-white-110nit-command-state = "dsi_hs_mode";

			mi,mdss-dsi-local-hbm-hlpm-white-110nit-command = [
				39 00 00 00 00 00 06 F0 55 AA 52 08 00
				/* AOD off */
				39 00 00 40 00 00 02 38 00
				39 00 00 00 00 00 02 2C 00
				/* Local HBM setting*/
				39 00 00 00 00 00 06 F0 55 AA 52 08 00
				39 00 00 40 00 00 02 6F 17
				39 00 00 40 00 00 03 B2 01 48
				39 00 00 40 00 00 06 F0 55 AA 52 08 02
				39 00 00 40 00 00 02 6F 08
				39 00 00 40 00 00 07 D0 0B 0A 0A EC 0B FD
				39 00 00 40 00 00 02 88 01
				39 00 00 40 00 00 02 6F 01
				39 00 00 40 00 00 05 88 02 1C 08 73
				39 00 00 40 00 00 03 87 1F FF
				39 00 00 00 20 00 02 85 01
			];
			mi,mdss-dsi-local-hbm-hlpm-white-110nit-command-update = <0x87 12 2>, <0xD0 8 6>, <0xB2 5 2>;
			mi,mdss-dsi-local-hbm-hlpm-white-110nit-command-state = "dsi_hs_mode";

			mi,mdss-dsi-local-hbm-normal-green-500nit-command = [
				39 00 00 00 00 00 06 F0 55 AA 52 08 00
				39 00 00 40 00 00 02 6F 17
				39 00 00 40 00 00 03 B2 01 48
				39 00 00 40 00 00 06 F0 55 AA 52 08 02
				39 00 00 40 00 00 02 6F 08
				39 00 00 40 00 00 07 D0 0B 0A 0A EC 0B FD
				39 00 00 40 00 00 02 88 01
				39 00 00 40 00 00 02 6F 01
				39 00 00 40 00 00 05 88 02 1C 08 73
				39 00 00 40 00 00 03 87 1F FF
				39 00 00 00 20 00 02 85 01
			];
			mi,mdss-dsi-local-hbm-normal-green-500nit-command-update = <0x87 9 2>, <0xD0 5 6>, <0xB2 2 2>;
			mi,mdss-dsi-local-hbm-normal-green-500nit-command-state = "dsi_hs_mode";

			mi,mdss-dsi-local-hbm-off-to-normal-command = [
				39 00 00 00 00 00 02 53 20
				39 00 00 40 00 00 03 51 00 00
				39 00 00 40 00 00 02 86 01
				39 00 00 00 00 00 03 87 0F FF
			];
			mi,mdss-dsi-local-hbm-off-to-normal-command-update = <0x51 1 2>;
			mi,mdss-dsi-local-hbm-off-to-normal-command-state = "dsi_hs_mode";

			mi,mdss-dsi-local-hbm-off-to-hbm-command = [
				39 00 00 00 00 00 02 53 20
				39 00 00 40 00 00 03 51 00 00
				39 00 00 40 00 00 02 86 01
				39 00 00 00 00 00 03 87 0F FF
			];
			mi,mdss-dsi-local-hbm-off-to-hbm-command-update = <0x51 1 2>;
			mi,mdss-dsi-local-hbm-off-to-hbm-command-state = "dsi_hs_mode";

			mi,mdss-dsi-local-hbm-off-to-hlpm-command = [
				/* local hbm off */
				39 00 00 00 00 00 02 53 20
				39 00 00 40 00 00 03 51 00 00
				39 00 00 40 00 00 02 86 01
				39 00 00 00 00 00 03 87 0F FF
				/* aod hbm */
				39 00 00 00 00 00 06 F0 55 AA 52 08 00
				39 00 00 40 00 00 05 51 00 F5 03 FF
				39 00 00 40 00 00 02 39 00
				39 00 00 00 00 00 02 2C 00
			];
			mi,mdss-dsi-local-hbm-off-to-hlpm-command-state = "dsi_hs_mode";

			mi,mdss-dsi-local-hbm-off-to-llpm-command = [
				/* local hbm off */
				39 00 00 00 00 00 02 53 20
				39 00 00 40 00 00 03 51 00 00
				39 00 00 40 00 00 02 86 01
				39 00 00 00 00 00 03 87 0F FF
				/* aod lbm */
				39 00 00 00 00 00 06 F0 55 AA 52 08 00
				39 00 00 40 00 00 05 51 00 14 01 FF
				39 00 00 40 00 00 02 39 00
				39 00 00 00 00 00 02 2C 00
			];
			mi,mdss-dsi-local-hbm-off-to-llpm-command-state = "dsi_hs_mode";

			mi,mdss-dsi-flat-mode-on-command = [
				/* page 0 */
				39 00 00 00 00 00 06 F0 55 AA 52 08 00
				/* 120Hz */
				39 00 00 40 00 00 02 2F 02
				/* GIR ON */
				39 00 00 20 14 00 02 5F 00
			];
			mi,mdss-dsi-flat-mode-on-command-state = "dsi_hs_mode";

			mi,mdss-dsi-flat-mode-off-command = [
				/* Page 0 */
				39 00 00 00 00 00 06 F0 55 AA 52 08 00
				/* 120Hz */
				39 00 00 40 00 00 02 2F 01
				/* GIR OFF */
				39 00 00 20 14 00 02 5F 01
			];
			mi,mdss-dsi-flat-mode-off-command-state = "dsi_hs_mode";

			mi,mdss-dsi-pre-doze-to-off-command = [
				39 01 00 00 00 00 06 F0 55 AA 52 08 01
				39 01 00 00 00 00 02 CE 0C];
			mi,mdss-dsi-pre-doze-to-off-command-state = "dsi_hs_mode";
		};
		timing@2{ /* 90hz */
			/*<flat on gamma, flat off gamma>*/
			mi,mdss-flat-status-control-gamma-cfg = <0x08 0x07>;
			mi,mdss-dsc-panel-id = <0x004C3953 0x00360200>;
			mi,mdss-dsi-dimmingon-command = [39 00 00 00 00 00 02 53 28];
			mi,mdss-dsi-dimmingon-command-state = "dsi_hs_mode";
			mi,mdss-dsi-dimmingoff-command = [39 00 00 00 00 00 02 53 20];
			mi,mdss-dsi-dimmingoff-command-state = "dsi_hs_mode";

			mi,mdss-dsi-hbm-on-command = [39 00 00 00 00 00 03 51 0F FF];
			mi,mdss-dsi-hbm-on-command-state = "dsi_hs_mode";
			mi,mdss-dsi-hbm-off-command = [39 00 00 00 00 00 03 51 07 FF];
			mi,mdss-dsi-hbm-off-command-state = "dsi_hs_mode";

			mi,mdss-dsi-doze-hbm-command = [
				39 00 00 00 00 00 06 F0 55 AA 52 08 00
				39 00 00 40 00 00 05 51 00 F5 03 FF
				39 00 00 40 00 00 02 39 00
				39 00 00 00 00 00 02 2C 00
			];
			mi,mdss-dsi-doze-hbm-command-state = "dsi_lp_mode";
			mi,mdss-dsi-doze-lbm-command = [
				39 00 00 00 00 00 06 F0 55 AA 52 08 00
				39 00 00 40 00 00 05 51 00 14 01 FF
				39 00 00 40 00 00 02 39 00
				39 00 00 00 00 00 02 2C 00
			];
			mi,mdss-dsi-doze-lbm-command-state = "dsi_lp_mode";

			mi,mdss-dsi-doze-hbm-nolp-command = [
				/* AOD off */
				39 00 00 00 00 00 06 F0 55 AA 52 08 00
				39 00 00 40 00 00 05 51 00 F5 03 FF
				39 00 00 40 00 00 02 38 00
				39 00 00 00 00 00 02 2C 00
			];
			mi,mdss-dsi-doze-hbm-nolp-command-state = "dsi_lp_mode";
			mi,mdss-dsi-doze-lbm-nolp-command = [
				/* AOD off */
				39 00 00 00 00 00 06 F0 55 AA 52 08 00
				39 00 00 40 00 00 05 51 00 14 01 FF
				39 00 00 40 00 00 02 38 00
				39 00 00 00 00 00 02 2C 00
			];
			mi,mdss-dsi-doze-lbm-nolp-command-state = "dsi_lp_mode";

			mi,mdss-dsi-doze-none-nolp-command = [
				/* AOD off */
				39 00 00 00 32 00 02 38 00
				39 00 00 00 00 00 02 2C 00
			];
			mi,mdss-dsi-doze-none-nolp-command-state = "dsi_lp_mode";

			mi,mdss-dsi-local-hbm-normal-white-1000nit-command = [
				39 00 00 00 00 00 06 F0 55 AA 52 08 00
				39 00 00 40 00 00 02 6F 17
				39 00 00 40 00 00 03 B2 01 48
				39 00 00 40 00 00 06 F0 55 AA 52 08 02
				39 00 00 40 00 00 02 6F 08
				39 00 00 40 00 00 07 D0 0B 0A 0A EC 0B FD
				39 00 00 40 00 00 02 88 01
				39 00 00 40 00 00 02 6F 01
				39 00 00 40 00 00 05 88 02 1C 08 73
				39 00 00 40 00 00 03 87 1F FF
				39 00 00 00 42 00 02 85 01
			];
			mi,mdss-dsi-local-hbm-normal-white-1000nit-command-update = <0x87 9 2>, <0xD0 5 6>, <0xB2 2 2>;
			mi,mdss-dsi-local-hbm-normal-white-1000nit-command-state = "dsi_hs_mode";

			mi,mdss-dsi-local-hbm-hlpm-white-1000nit-command = [
				/* AOD off */
				39 00 00 00 00 00 06 F0 55 AA 52 08 00
				39 00 00 40 00 00 02 38 00
				39 00 00 00 00 00 02 2C 00
				/* Local HBM setting*/
				39 00 00 00 00 00 06 F0 55 AA 52 08 00
				39 00 00 40 00 00 02 6F 17
				39 00 00 40 00 00 03 B2 01 48
				39 00 00 40 00 00 06 F0 55 AA 52 08 02
				39 00 00 40 00 00 02 6F 08
				39 00 00 40 00 00 07 D0 0B 0A 0A EC 0B FD
				39 00 00 40 00 00 02 88 01
				39 00 00 40 00 00 02 6F 01
				39 00 00 40 00 00 05 88 02 1C 08 73
				39 00 00 40 00 00 03 87 1F FF
				39 00 00 00 42 00 02 85 01
			];
			mi,mdss-dsi-local-hbm-hlpm-white-1000nit-command-update = <0x87 12 2>, <0xD0 8 6>, <0xB2 5 2>;
			mi,mdss-dsi-local-hbm-hlpm-white-1000nit-command-state = "dsi_hs_mode";

			mi,mdss-dsi-local-hbm-normal-white-110nit-command = [
				39 00 00 00 00 00 06 F0 55 AA 52 08 00
				39 00 00 40 00 00 02 6F 17
				39 00 00 40 00 00 03 B2 01 48
				39 00 00 40 00 00 06 F0 55 AA 52 08 02
				39 00 00 40 00 00 02 6F 08
				39 00 00 40 00 00 07 D0 0B 0A 0A EC 0B FD
				39 00 00 40 00 00 02 88 01
				39 00 00 40 00 00 02 6F 01
				39 00 00 40 00 00 05 88 02 1C 08 73
				39 00 00 40 00 00 03 87 1F FF
				39 00 00 00 42 00 02 85 01
			];
			mi,mdss-dsi-local-hbm-normal-white-110nit-command-update = <0x87 9 2>, <0xD0 5 6>, <0xB2 2 2>;
			mi,mdss-dsi-local-hbm-normal-white-110nit-command-state = "dsi_hs_mode";

			mi,mdss-dsi-local-hbm-hlpm-white-110nit-command = [
				39 00 00 00 00 00 06 F0 55 AA 52 08 00
				/* AOD off */
				39 00 00 40 00 00 02 38 00
				39 00 00 00 00 00 02 2C 00
				/* Local HBM setting*/
				39 00 00 00 00 00 06 F0 55 AA 52 08 00
				39 00 00 40 00 00 02 6F 17
				39 00 00 40 00 00 03 B2 01 48
				39 00 00 40 00 00 06 F0 55 AA 52 08 02
				39 00 00 40 00 00 02 6F 08
				39 00 00 40 00 00 07 D0 0B 0A 0A EC 0B FD
				39 00 00 40 00 00 02 88 01
				39 00 00 40 00 00 02 6F 01
				39 00 00 40 00 00 05 88 02 1C 08 73
				39 00 00 40 00 00 03 87 1F FF
				39 00 00 00 42 00 02 85 01
			];
			mi,mdss-dsi-local-hbm-hlpm-white-110nit-command-update = <0x87 12 2>, <0xD0 8 6>, <0xB2 5 2>;
			mi,mdss-dsi-local-hbm-hlpm-white-110nit-command-state = "dsi_hs_mode";

			mi,mdss-dsi-local-hbm-normal-green-500nit-command = [
				39 00 00 00 00 00 06 F0 55 AA 52 08 00
				39 00 00 40 00 00 02 6F 17
				39 00 00 40 00 00 03 B2 01 48
				39 00 00 40 00 00 06 F0 55 AA 52 08 02
				39 00 00 40 00 00 02 6F 08
				39 00 00 40 00 00 07 D0 0B 0A 0A EC 0B FD
				39 00 00 40 00 00 02 88 01
				39 00 00 40 00 00 02 6F 01
				39 00 00 40 00 00 05 88 02 1C 08 73
				39 00 00 40 00 00 03 87 1F FF
				39 00 00 00 42 00 02 85 01
			];
			mi,mdss-dsi-local-hbm-normal-green-500nit-command-update = <0x87 9 2>, <0xD0 5 6>, <0xB2 2 2>;
			mi,mdss-dsi-local-hbm-normal-green-500nit-command-state = "dsi_hs_mode";

			mi,mdss-dsi-local-hbm-off-to-normal-command = [
				39 00 00 00 00 00 02 53 20
				39 00 00 40 00 00 03 51 00 00
				39 00 00 40 00 00 02 86 01
				39 00 00 00 00 00 03 87 0F FF
			];
			mi,mdss-dsi-local-hbm-off-to-normal-command-update = <0x51 1 2>;
			mi,mdss-dsi-local-hbm-off-to-normal-command-state = "dsi_hs_mode";

			mi,mdss-dsi-local-hbm-off-to-hbm-command = [
				39 00 00 00 00 00 02 53 20
				39 00 00 40 00 00 03 51 00 00
				39 00 00 40 00 00 02 86 01
				39 00 00 00 00 00 03 87 0F FF
			];
			mi,mdss-dsi-local-hbm-off-to-hbm-command-update = <0x51 1 2>;
			mi,mdss-dsi-local-hbm-off-to-hbm-command-state = "dsi_hs_mode";

			mi,mdss-dsi-local-hbm-off-to-hlpm-command = [
				/* local hbm off */
				39 00 00 00 00 00 02 53 20
				39 00 00 40 00 00 03 51 00 00
				39 00 00 40 00 00 02 86 01
				39 00 00 00 00 00 03 87 0F FF
				/* aod hbm */
				39 00 00 00 00 00 06 F0 55 AA 52 08 00
				39 00 00 40 00 00 05 51 00 F5 03 FF
				39 00 00 40 00 00 02 39 00
				39 00 00 00 00 00 02 2C 00
			];
			mi,mdss-dsi-local-hbm-off-to-hlpm-command-state = "dsi_hs_mode";

			mi,mdss-dsi-local-hbm-off-to-llpm-command = [
				/* local hbm off */
				39 00 00 00 00 00 02 53 20
				39 00 00 40 00 00 03 51 00 00
				39 00 00 40 00 00 02 86 01
				39 00 00 00 00 00 03 87 0F FF
				/* aod lbm */
				39 00 00 00 00 00 06 F0 55 AA 52 08 00
				39 00 00 40 00 00 05 51 00 14 01 FF
				39 00 00 40 00 00 02 39 00
				39 00 00 00 00 00 02 2C 00
			];
			mi,mdss-dsi-local-hbm-off-to-llpm-command-state = "dsi_hs_mode";

			mi,mdss-dsi-flat-mode-on-command = [
				/* page 0 */
				39 00 00 00 00 00 06 F0 55 AA 52 08 00
				/* 90Hz */
				39 00 00 40 00 00 02 2F 08
				/* GIR ON */
				39 00 00 20 14 00 02 5F 00
			];
			mi,mdss-dsi-flat-mode-on-command-state = "dsi_hs_mode";

			mi,mdss-dsi-flat-mode-off-command = [
				/* page 0 */
				39 00 00 00 00 00 06 F0 55 AA 52 08 00
				/* 90Hz */
				39 00 00 40 00 00 02 2F 07
				/* GIR OFF */
				39 00 00 20 14 00 02 5F 01
			];
			mi,mdss-dsi-flat-mode-off-command-state = "dsi_hs_mode";

			mi,mdss-dsi-pre-doze-to-off-command = [
				39 01 00 00 00 00 06 F0 55 AA 52 08 01
				39 01 00 00 00 00 02 CE 0C];
			mi,mdss-dsi-pre-doze-to-off-command-state = "dsi_hs_mode";
		};
	};
};
